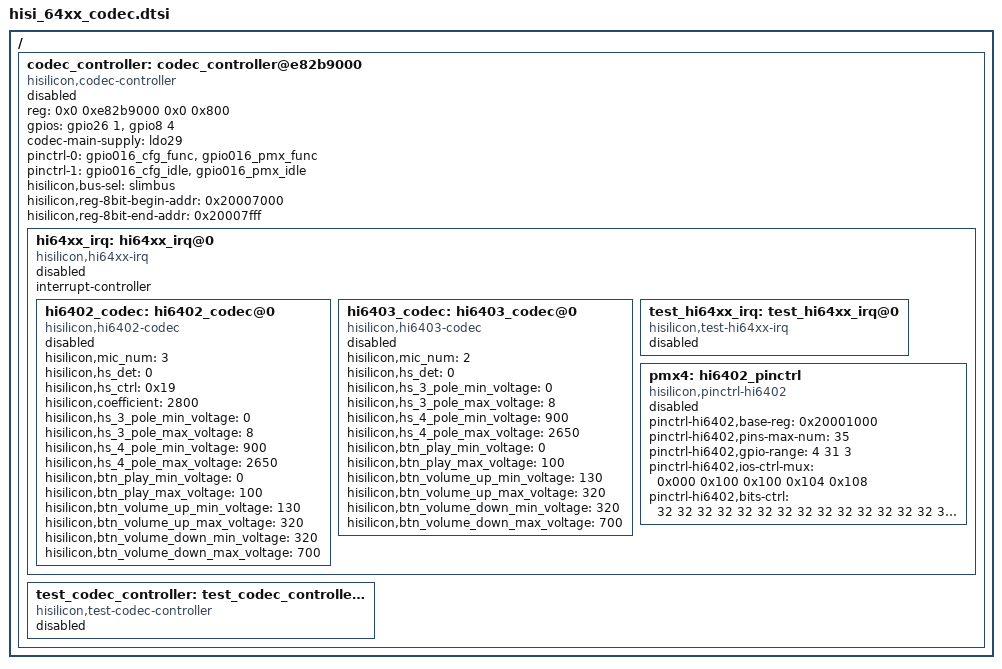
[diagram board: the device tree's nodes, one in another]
/*
 *  Copyright (C) 2014 Hisilicon Ltd.
 *
 *  This program is free software; you can redistribute it and/or modify
 *  it under the terms of the GNU General Public License version 2 as
 *  publishhed by the Free Software Foundation.
 */

/ {
	codec_controller: codec_controller@e82b9000 {
		compatible = "hisilicon,codec-controller";
		/* ssi base-addr & addr-range(0x200 << 2) */
		reg = <0x0 0xe82b9000 0x0 0x800>;
		/* irq & reset */
		gpios = <&gpio26 1 0>, <&gpio8 4 0>;
		codec-main-supply = <&ldo29>;
		/* ssi pinctrl */
		pinctrl-names = "default", "idle";
		pinctrl-0 = <&gpio016_cfg_func &gpio016_pmx_func>;
		pinctrl-1 = <&gpio016_cfg_idle &gpio016_pmx_idle>;
		/* select slimbus or ssi */
		hisilicon,bus-sel = "slimbus";
		hisilicon,reg-8bit-begin-addr = <0x20007000>;
		hisilicon,reg-8bit-end-addr = <0x20007fff>;
		status = "disabled";

		hi64xx_irq: hi64xx_irq@0 {
			compatible = "hisilicon,hi64xx-irq";
			#interrupt-cells = <2>;
			interrupt-controller;
			status = "disabled";

			hi6402_codec: hi6402_codec@0{
				compatible = "hisilicon,hi6402-codec";
				hisilicon,mic_num = <3>;
				hisilicon,hs_det = <0>;
				hisilicon,hs_ctrl = <0x19>;
				hisilicon,coefficient = <2800>;
				hisilicon,hs_3_pole_min_voltage = <0>;
				hisilicon,hs_3_pole_max_voltage = <8>;
				hisilicon,hs_4_pole_min_voltage = <900>;
				hisilicon,hs_4_pole_max_voltage = <2650>;
				hisilicon,btn_play_min_voltage = <0>;
				hisilicon,btn_play_max_voltage = <100>;
				hisilicon,btn_volume_up_min_voltage = <130>;
				hisilicon,btn_volume_up_max_voltage = <320>;
				hisilicon,btn_volume_down_min_voltage = <320>;
				hisilicon,btn_volume_down_max_voltage = <700>;
				status = "disabled";
			};

			hi6403_codec: hi6403_codec@0{
				compatible = "hisilicon,hi6403-codec";
				hisilicon,mic_num = <2>;
				hisilicon,hs_det = <0>;
				hisilicon,hs_3_pole_min_voltage = <0>;
				hisilicon,hs_3_pole_max_voltage = <8>;
				hisilicon,hs_4_pole_min_voltage = <900>;
				hisilicon,hs_4_pole_max_voltage = <2650>;
				hisilicon,btn_play_min_voltage = <0>;
				hisilicon,btn_play_max_voltage = <100>;
				hisilicon,btn_volume_up_min_voltage = <130>;
				hisilicon,btn_volume_up_max_voltage = <320>;
				hisilicon,btn_volume_down_min_voltage = <320>;
				hisilicon,btn_volume_down_max_voltage = <700>;
				status = "disabled";
			};

			test_hi64xx_irq: test_hi64xx_irq@0 {
                               compatible = "hisilicon,test-hi64xx-irq";
                               status = "disabled";
			};

			pmx4: hi6402_pinctrl {
				compatible = "hisilicon,pinctrl-hi6402";
				pinctrl-hi6402,base-reg = <0x20001000>;
				pinctrl-hi6402,pins-max-num = <35>;
				#gpio-range-cells = <3>;
				#pinctrl-hi6402,gpio-range-cells = <3>;
				pinctrl-hi6402,gpio-range = <4 31 3>;	/* pin base, nr pins & gpio function */
				pinctrl-hi6402,ios-ctrl-mux = <
					0x000		/* IOS_MF_CTRL0, value */
					0x100 		/* IOS_AF_CTRL0, value */
					0x100		/* IOS_AF_CTRL0, value */
					0x104		/* IOS_AF_CTRL1, value */
					0x108		/* IOS_MF_CTRL2, value */
				>;
				pinctrl-hi6402,bits-ctrl = <
					32 32 32 32 32		/* PIN:MCLK,		  NUM:0 */
					32 32 32 32 32		/* PIN:CLK32,		  NUM:1 */
					32 32 32 32 32		/* PIN:RESET,		  NUM:2 */
					32 32 32 32 32		/* PIN:DFT_MODE,	  NUM:3 */
					32 2  3  0  0		/* PIN:GPIO0,		  NUM:4 */
					8  0  32 1  15		/* PIN:DMIC_CLK0(GPIO1),  NUM:5 */
					8  32 32 2  16		/* PIN:DMIC_DATA0(GPIO2), NUM:6 */
					9  32 5  3  17		/* PIN:DMIC_CLK1(GPIO3),  NUM:7 */
					9  32 5  4  18		/* PIN:DMIC_DATA1(GPIO4), NUM:8 */
					1  2  3  5  32		/* PIN:SSI_DATA(GPIO5),   NUM:9 */
					2  32 32 6  32		/* PIN:IRQ_N(GPIO6),      NUM:10 */
					4  1  32 7  32		/* PIN:I2S1_SYNC(GPIO7),  NUM:11 */
					4  1  32 8  32		/* PIN:I2S1_CLK(GPIO8),   NUM:12 */
					4  32 32 9  1		/* PIN:I2S1_SDI(GPIO9),   NUM:13 */
					4  32 32 10 2		/* PIN:I2S1_SDO(GPIO10),  NUM:14 */
					5  0  32 11 3		/* PIN:I2S2_SYNC(GPIO11), NUM:15 */
					5  0  32 12 4		/* PIN:I2S2_CLK(GPIO12),  NUM:16 */
					5  0  4  13 5		/* PIN:I2S2_SDI(GPIO13),  NUM:17 */
					5  0  4  14 6		/* PIN:I2S2_SDO(GPIO14),  NUM:18 */
					6  32 32 15 7		/* PIN:I2S3_SYNC(GPIO15), NUM:19 */
					6  32 32 16 8		/* PIN:I2S3_CLK(GPIO16),  NUM:20 */
					6  32 32 17 9		/* PIN:I2S3_SDI(GPIO17),  NUM:21 */
					6  32 32 18 10		/* PIN:I2S3_SDO(GPIO18),  NUM:22 */
					7  32 32 19 11		/* PIN:I2S4_SYNC(GPIO19), NUM:23 */
					7  32 32 20 12		/* PIN:I2S4_CLK(GPIO20),  NUM:24 */
					7  32 32 21 13		/* PIN:I2S4_SDI(GPIO21),  NUM:25 */
					7  32 32 22 14		/* PIN:I2S4_SDO(GPIO22),  NUM:26 */
					10 32 32 23 19		/* PIN:SPK_CLK(GPIO23),   NUM:27 */
					10 32 32 24 20		/* PIN:SPK_DATA(GPIO24),  NUM:28 */
					11 32 32 25 21		/* PIN:GPIO25,            NUM:29 */
					12 32 32 26 22		/* PIN:GPIO26,            NUM:30 */
					12 32 32 27 23		/* PIN:GPIO27,            NUM:31 */
					32 32 32 28 24		/* PIN:GPIO28,            NUM:32 */
					32 32 32 29 25		/* PIN:GPIO29,            NUM:33 */
					32 32 32 30 26		/* PIN:GPIO30,            NUM:34 */
				>;
				status = "disabled";
			};

		};

		test_codec_controller: test_codec_controller@0 {
			compatible = "hisilicon,test-codec-controller";
			status = "disabled";
		};
	};
};
